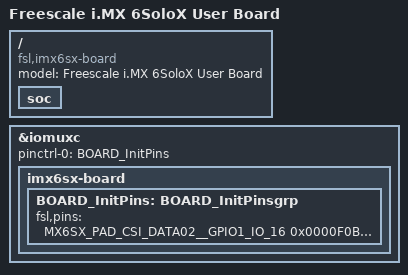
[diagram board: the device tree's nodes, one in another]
/***********************************************************************************************************************
 * This file was generated by the MCUXpresso Config Tools. Any manual edits made to this file
 * will be overwritten if the respective MCUXpresso Config Tools is used to update this file.
 **********************************************************************************************************************/

/*
 * TEXT BELOW IS USED AS SETTING FOR TOOLS *************************************
!!GlobalInfo
product: Pins v6.0
processor: MCIMX6XxxVM
package_id: MCIMX6X4EVM10AB
mcu_data: i_mx_1_0
processor_version: 6.0.0
pin_labels:
- {pin_num: E22, pin_signal: LCD1_RESET, label: BUTTON, identifier: BUTTON}
- {pin_num: Y9, pin_signal: SD4_RESET_B, label: LED, identifier: LED}
- {pin_num: F13, pin_signal: SD2_DATA1, label: LED_TEST, identifier: LED_TEST}
- {pin_num: G13, pin_signal: SD2_DATA0, label: BUT1_TEST, identifier: BUT1_TEST}
- {pin_num: A8, pin_signal: RGMII2_RD2, label: BUT2_TEST, identifier: BUT2_TEST}
- {pin_num: N19, pin_signal: CSI_DATA04, label: BUT2_TEST, identifier: BUT2_TEST}
 * BE CAREFUL MODIFYING THIS COMMENT - IT IS YAML SETTINGS FOR TOOLS ***********
 */

///dts-v1/;

#include "skeleton.dtsi"
#include "imx6sx-pinfunc.h"

/ {
    model = "Freescale i.MX 6SoloX User Board";
    compatible = "fsl,imx6sx-board", "fsl,imx6sx";

    soc {
        #address-cells = <1>;
        #size-cells = <1>;

        /*iomuxc: iomuxc@020e0000 {
            compatible = "fsl,imx6sx-iomuxc";
            reg = <0x020e0000 0x4000>;
        };*/
    };
};

&iomuxc {
    pinctrl-names = "default";
    pinctrl-0 = <&BOARD_InitPins>;

    imx6sx-board {

        BOARD_InitPins: BOARD_InitPinsgrp {                /*!< Function assigned for the core: Cortex-M4[cm4] */
/*
 * TEXT BELOW IS USED AS SETTING FOR TOOLS *************************************
BOARD_InitPins:
- options: {callFromInitBoot: 'false', coreID: cm4}
- pin_list:
  - {pin_num: E22, peripheral: GPIO3, signal: 'io, 27', pin_signal: LCD1_RESET, direction: INPUT, PUS: OHM_22K_PU, PUE: PULL}
  - {pin_num: Y9, peripheral: GPIO6, signal: 'io, 22', pin_signal: SD4_RESET_B, direction: OUTPUT}
  - {pin_num: F13, peripheral: GPIO6, signal: 'io, 9', pin_signal: SD2_DATA1, direction: OUTPUT, PUS: no_init}
  - {pin_num: G13, peripheral: GPIO6, signal: 'io, 8', pin_signal: SD2_DATA0, direction: INPUT, PUS: OHM_22K_PU, PUE: PULL}
  - {pin_num: N19, peripheral: GPIO1, signal: 'io, 18', pin_signal: CSI_DATA04, direction: INPUT, PUS: OHM_22K_PU, PUE: PULL}
 * BE CAREFUL MODIFYING THIS COMMENT - IT IS YAML SETTINGS FOR TOOLS ***********
 */
            fsl,pins = <
                MX6SX_PAD_CSI_DATA02__GPIO1_IO_16          0x0000F0B0
                MX6SX_PAD_CSI_DATA03__GPIO1_IO_17          0x0000F0B0
                MX6SX_PAD_CSI_DATA04__GPIO1_IO_18          0x0000F0B0
                MX6SX_PAD_CSI_DATA05__GPIO1_IO_19          0x0000F0B0
                MX6SX_PAD_CSI_DATA06__GPIO1_IO_20          0x0000F0B0
                MX6SX_PAD_ENET1_CRS__GPIO2_IO_1            0x0000F0B0
                MX6SX_PAD_ENET1_RX_CLK__GPIO2_IO_4         0x0000F0B0
                MX6SX_PAD_ENET2_COL__GPIO2_IO_6            0x0000F0B0
                MX6SX_PAD_KEY_COL0__GPIO2_IO_10            0x0000F0B0
                MX6SX_PAD_KEY_COL2__GPIO2_IO_12            0x0000F0B0
                MX6SX_PAD_KEY_COL3__GPIO2_IO_13            0x0000F0B0
                MX6SX_PAD_KEY_COL4__GPIO2_IO_14            0x0000F0B0
                MX6SX_PAD_KEY_ROW2__GPIO2_IO_17            0x0000F0B0
                MX6SX_PAD_KEY_ROW3__GPIO2_IO_18            0x0000F0B0
                MX6SX_PAD_LCD1_CLK__GPIO3_IO_0             0x0000F0B0
                MX6SX_PAD_LCD1_DATA00__GPIO3_IO_1          0x0000F0B0
                MX6SX_PAD_LCD1_DATA01__GPIO3_IO_2          0x0000F0B0
                MX6SX_PAD_LCD1_DATA02__GPIO3_IO_3          0x0000F0B0
                MX6SX_PAD_LCD1_DATA03__GPIO3_IO_4          0x0000F0B0
                MX6SX_PAD_LCD1_DATA04__GPIO3_IO_5          0x0000F0B0
                MX6SX_PAD_LCD1_DATA05__GPIO3_IO_6          0x0000F0B0
                MX6SX_PAD_LCD1_DATA06__GPIO3_IO_7          0x0000F0B0
                MX6SX_PAD_LCD1_DATA07__GPIO3_IO_8          0x0000F0B0
                MX6SX_PAD_LCD1_DATA10__GPIO3_IO_11         0x0000F0B0
                MX6SX_PAD_LCD1_DATA11__GPIO3_IO_12         0x0000F0B0
                MX6SX_PAD_LCD1_DATA12__GPIO3_IO_13         0x0000F0B0
                MX6SX_PAD_QSPI1A_SS1_B__GPIO4_IO_23        0x0000F0B0
                MX6SX_PAD_QSPI1B_DATA0__GPIO4_IO_24        0x0000F0B0
                MX6SX_PAD_QSPI1B_DATA1__GPIO4_IO_25        0x0000F0B0
                MX6SX_PAD_QSPI1B_DQS__GPIO4_IO_28          0x0000F0B0
                MX6SX_PAD_SD1_DATA0__GPIO6_IO_2            0x0000F0B0
                MX6SX_PAD_SD1_DATA1__GPIO6_IO_3            0x0000F0B0
                MX6SX_PAD_SD2_CLK__GPIO6_IO_6              0x0000F0B0
                MX6SX_PAD_SD2_CMD__GPIO6_IO_7              0x0000F0B0
                MX6SX_PAD_SD2_DATA0__GPIO6_IO_8            0x0000F0B0
                MX6SX_PAD_SD2_DATA1__GPIO6_IO_9            0x0000F0B0
                MX6SX_PAD_SD2_DATA2__GPIO6_IO_10           0x0000F0B0
                MX6SX_PAD_SD2_DATA3__GPIO6_IO_11           0x0000F0B0
                MX6SX_PAD_SD4_CLK__GPIO6_IO_12             0x0000F0B0
                MX6SX_PAD_SD4_CMD__GPIO6_IO_13             0x0000F0B0
                MX6SX_PAD_SD4_DATA0__GPIO6_IO_14           0x0000F0B0
                MX6SX_PAD_SD4_DATA1__GPIO6_IO_15           0x0000F0B0
                MX6SX_PAD_SD4_DATA2__GPIO6_IO_16           0x0000F0B0
                MX6SX_PAD_SD4_DATA3__GPIO6_IO_17           0x0000F0B0
                MX6SX_PAD_SD4_DATA4__GPIO6_IO_18           0x0000F0B0
                MX6SX_PAD_SD4_DATA5__GPIO6_IO_19           0x0000F0B0
                MX6SX_PAD_SD4_DATA6__GPIO6_IO_20           0x0000F0B0
                MX6SX_PAD_SD4_DATA7__GPIO6_IO_21           0x0000F0B0
                MX6SX_PAD_SD4_RESET_B__GPIO6_IO_22         0x0000F0B0
            >;
        };

    };
};

